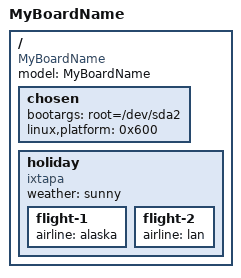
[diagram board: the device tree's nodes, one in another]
// SPDX-License-Identifier: (GPL-2.0-or-later OR BSD-2-Clause)
/dts-v1/;
/ {
	model = "MyBoardName";
	compatible = "MyBoardName", "MyBoardFamilyName";
	#address-cells = <2>;
	#size-cells = <2>;
	chosen {
		bootargs = "root=/dev/sda2";
		linux,platform = <0x600>;
	};
	holiday {
		compatible = "ixtapa", "mexico";
		weather = "sunny";
		status = "okay";
		flight-1 {
			airline = "alaska";
		};
		flight-2 {
			airline = "lan";
		};
	};
};
